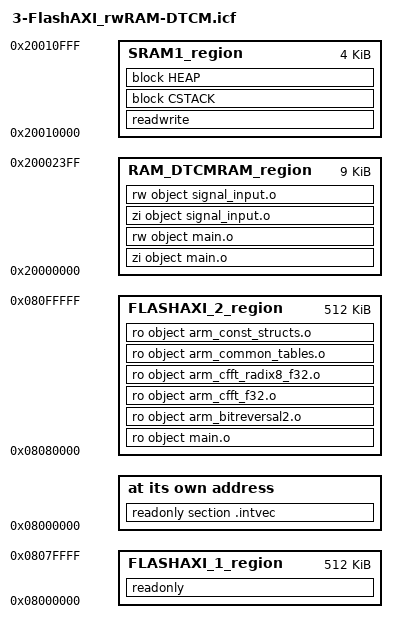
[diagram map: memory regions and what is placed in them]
/*###ICF### Section handled by ICF editor, don't touch! ****/
/*-Editor annotation file-*/
/* IcfEditorFile="$TOOLKIT_DIR$\config\ide\IcfEditor\cortex_v1_0.xml" */
/*-Specials-*/
define symbol __ICFEDIT_intvec_start__ = 0x08000000;

/*= Code region(s) ===================================== */
/* -- Program region in internal Flash ----------------- */
define symbol __ICFEDIT_region_FLASHAXI_1_start__ = 0x08000000;
define symbol __ICFEDIT_region_FLASHAXI_1_end__   = 0x0807FFFF;
define symbol __ICFEDIT_region_FLASHAXI_2_start__ = 0x08080000;
define symbol __ICFEDIT_region_FLASHAXI_2_end__   = 0x80FFFFF;

/*= Data region(s) ===================================== */
/* RAM -- +RW +ZI region ------------------------------- */
define symbol __ICFEDIT_region_RAM_DTCMRAM_start__ = 0x20000000;
define symbol __ICFEDIT_region_RAM_DTCMRAM_end__   = 0x200023FF;
define symbol __ICFEDIT_region_SRAM1_start__       = 0x20010000;
define symbol __ICFEDIT_region_SRAM1_end__         = 0x20010FFF;

/*= STACK and Heap Sizes =============================== */
define symbol __ICFEDIT_size_cstack__ = 0x200;
define symbol __ICFEDIT_size_heap__   = 0x00;
/**** End of ICF editor section. ###ICF###*/


define memory mem with size = 4G;
define region FLASHAXI_1_region   = mem:[from __ICFEDIT_region_FLASHAXI_1_start__   to __ICFEDIT_region_FLASHAXI_1_end__];
define region SRAM1_region        = mem:[from __ICFEDIT_region_SRAM1_start__   to __ICFEDIT_region_SRAM1_end__];
define region FLASHAXI_2_region   = mem:[from __ICFEDIT_region_FLASHAXI_2_start__ to __ICFEDIT_region_FLASHAXI_2_end__];
define region RAM_DTCMRAM_region  = mem:[from __ICFEDIT_region_RAM_DTCMRAM_start__ to __ICFEDIT_region_RAM_DTCMRAM_end__];

define block CSTACK    with alignment = 8, size = __ICFEDIT_size_cstack__   { };
define block HEAP      with alignment = 8, size = __ICFEDIT_size_heap__     { };

initialize by copy {  readwrite,
                      rw object main.o,
                      rw object signal_input.o	 };
do not initialize  { section .noinit };

place at address mem:__ICFEDIT_intvec_start__ { readonly section .intvec };

place in FLASHAXI_1_region           { readonly };
place in SRAM1_region   { readwrite,
                        block CSTACK, block HEAP };
place in FLASHAXI_2_region   { ro object main.o, 
                               ro object arm_bitreversal2.o,
                               ro object arm_cfft_f32.o,
                               ro object arm_cfft_radix8_f32.o,
                               ro object arm_common_tables.o,
                               ro object arm_const_structs.o };

place in RAM_DTCMRAM_region   { zi object main.o,
                                rw object main.o,
                                zi object signal_input.o,
                                rw object signal_input.o};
